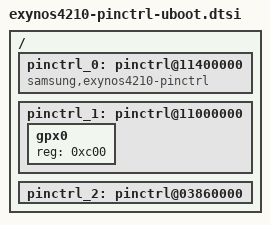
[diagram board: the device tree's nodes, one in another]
/*
 * U-Boot additions to enable a generic Exynos GPIO driver
 *
 * Copyright (c) 2014 Google, Inc
 *
 * SPDX-License-Identifier:	GPL-2.0+
 */

/{
	pinctrl_0: pinctrl@11400000 {
		#address-cells = <1>;
		#size-cells = <0>;
		compatible = "samsung,exynos4210-pinctrl";
	};

	pinctrl_1: pinctrl@11000000 {
		#address-cells = <1>;
		#size-cells = <0>;
		gpx0: gpx0 {
			reg = <0xc00>;
		};
	};

	pinctrl_2: pinctrl@03860000 {
		#address-cells = <1>;
		#size-cells = <0>;
	};

};
